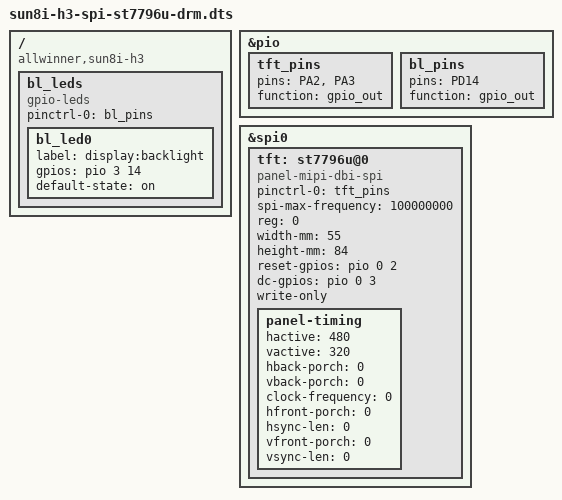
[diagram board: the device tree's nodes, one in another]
/dts-v1/;
/plugin/;

/ {
	compatible = "allwinner,sun8i-h3";

	fragment@0 {
		target-path = "/";
		__overlay__ {
			bl_leds {
				compatible = "gpio-leds";

				pinctrl-names = "default";
				pinctrl-0 = <&bl_pins>;

				bl_led0 {
					label = "display:backlight";
					gpios = <&pio 3 14 0>;
					default-state = "on";
				};
			};
		};
	};

	fragment@1 {
		target = <&pio>;
		__overlay__ {
			tft_pins: tft_pins {
				pins = "PA2", "PA3";
				function = "gpio_out";
			};

			bl_pins: bl_pins {
				pins = "PD14";
				function = "gpio_out";
			};
		};
	};

	fragment@2 {
		target = <&spi0>;
		__overlay__ {
			status = "okay";

			tft: st7796u@0 {
				#address-cells = <1>;
				#size-cells = <1>;

				pinctrl-names = "default";
				pinctrl-0 = <&tft_pins>;

				compatible = "panel-mipi-dbi-spi";

				spi-max-frequency = <100000000>;
				reg = <0>;

				width-mm = <55>;
				height-mm = <84>;

				reset-gpios = <&pio 0 2 0>;
				dc-gpios = <&pio 0 3 0>;
				write-only;

				status = "okay";

				panel-timing {
					hactive = <480>;
					vactive = <320>;
					hback-porch = <0>;
					vback-porch = <0>;

					clock-frequency = <0>;
					hfront-porch = <0>;
					hsync-len = <0>;
					vfront-porch = <0>;
					vsync-len = <0>;
				};
			};
		};
	};
};
